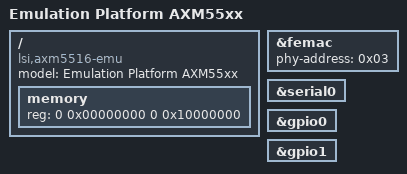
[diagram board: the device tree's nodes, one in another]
/*
 * arch/arm/boot/dts/axm5504-emulation.dts
 *
 * Copyright (C) 2013 LSI
 *
 * This program is free software; you can redistribute it and/or modify
 * it under the terms of the GNU General Public License as published by
 * the Free Software Foundation; either version 2 of the License, or
 * (at your option) any later version.
 */

/dts-v1/;

/memreserve/ 0x00000000 0x00400000;

/include/ "axm55xx.dtsi"
/include/ "axm5504-cpus.dtsi"

/ {
	model = "Emulation Platform AXM55xx";
	compatible = "lsi,axm5516-emu", "lsi,axm5516";

	memory {
		device_type = "memory";
		reg = <0 0x00000000 0 0x10000000>;
	};
};

&femac {
	status = "okay";
	phy-address = <0x03>;
};

&serial0 {
	status = "okay";
};

&gpio0 {
	status = "okay";
};

&gpio1 {
	status = "okay";
};
